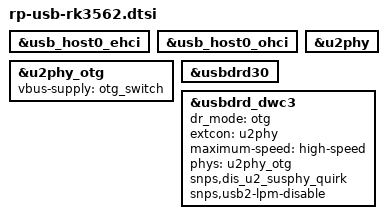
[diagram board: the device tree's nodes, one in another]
&usb_host0_ehci {
        status = "okay";
};

&usb_host0_ohci {
        status = "okay";
};

&u2phy {
	status = "okay";
};

&u2phy_otg {
	status = "okay";
	vbus-supply = <&otg_switch>;
};

&usbdrd30 {
	status = "okay";
};

&usbdrd_dwc3 {
	status = "okay";

	dr_mode = "otg";
	extcon = <&u2phy>;
	maximum-speed = "high-speed";
	phys = <&u2phy_otg>;
	phy-names = "usb2-phy";
	snps,dis_u2_susphy_quirk;
	snps,usb2-lpm-disable;
};
